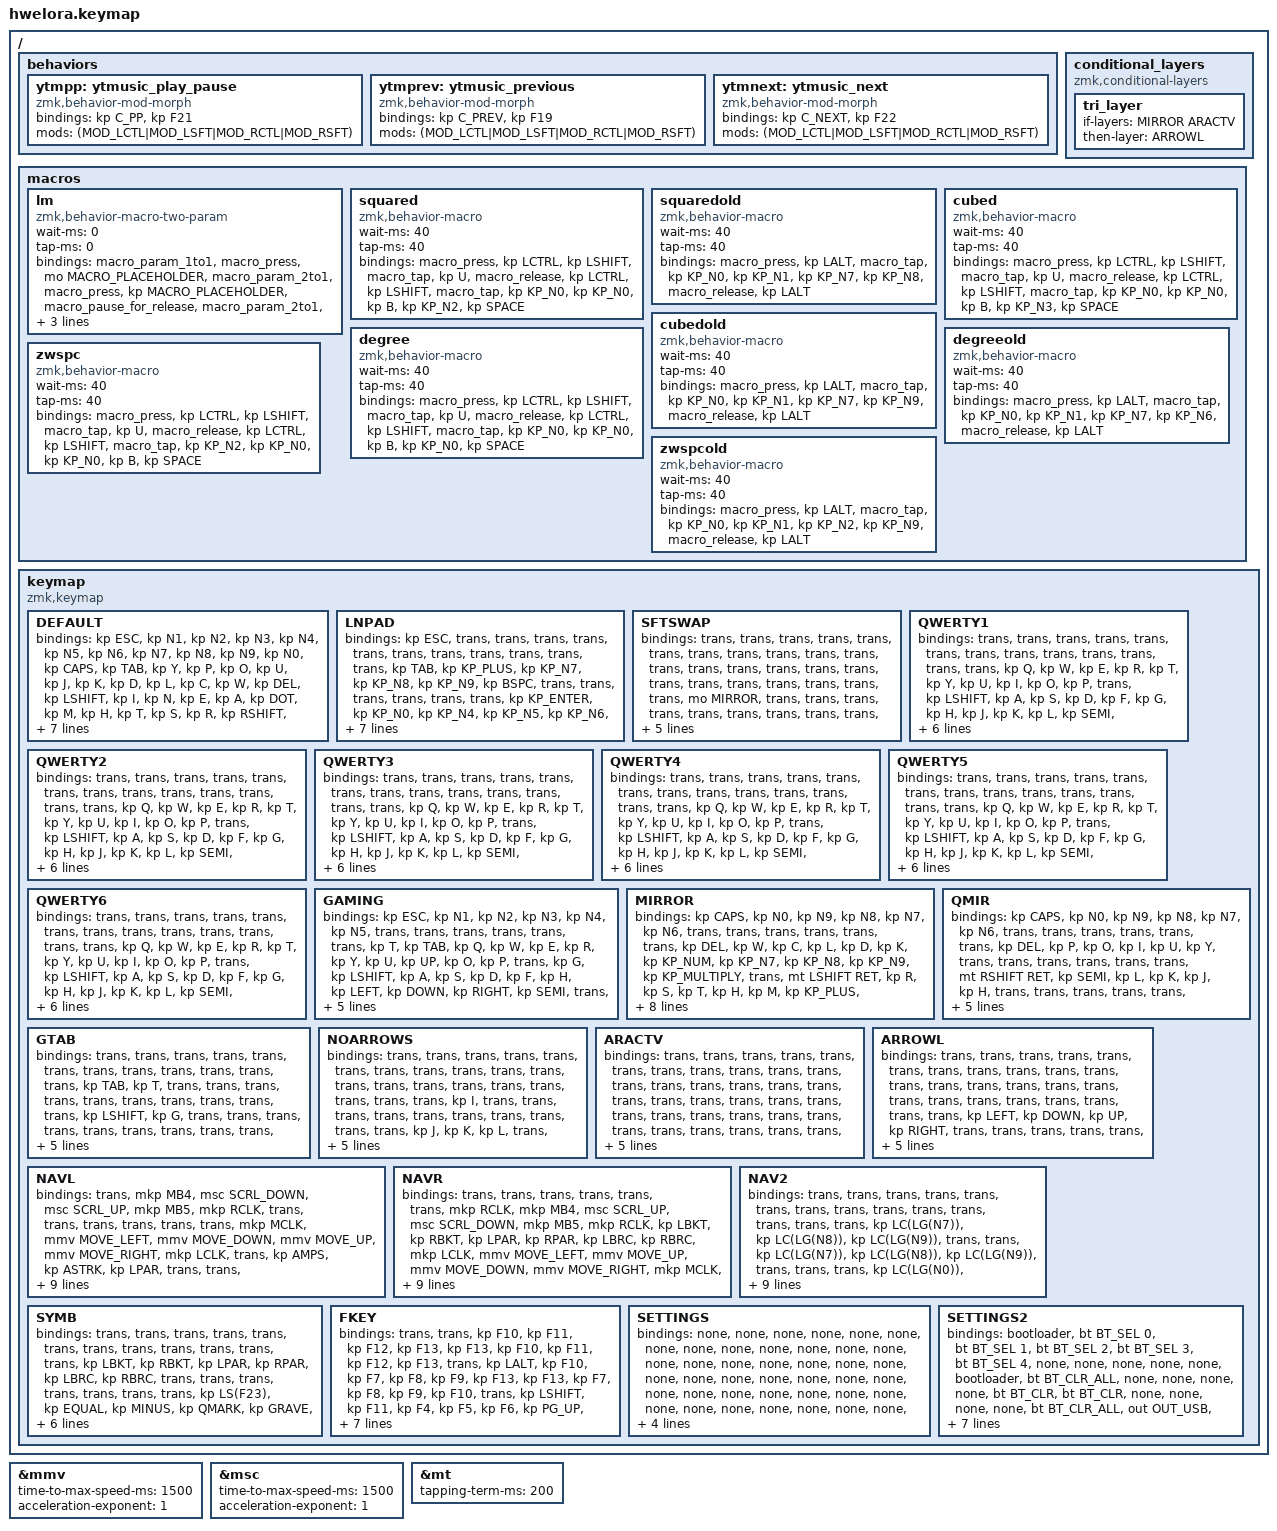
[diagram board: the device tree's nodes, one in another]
#include <behaviors.dtsi>
#include <dt-bindings/zmk/keys.h>
#include <dt-bindings/zmk/bt.h>
#include <dt-bindings/zmk/outputs.h>
#define ZMK_POINTING_DEFAULT_MOVE_VAL 2000
#define ZMK_POINTING_DEFAULT_SCRL_VAL 200 
#include <dt-bindings/zmk/pointing.h>
&mmv {
    time-to-max-speed-ms = <1500>;
    acceleration-exponent = <1>;
};
&msc {
    time-to-max-speed-ms = <1500>;
    acceleration-exponent = <1>;
};

#define DEFAULT 0
#define LNPAD	1
#define SFTSWAP 2
#define QWERTY1   3
#define QWERTY2   4
#define QWERTY3   5
#define QWERTY4   6
#define QWERTY5   7
#define QWERTY6   8
#define GAMING   9
#define MIRROR   10
#define QMIR   11
#define GTAB   12
#define NOARROWS   13
#define ARACTV   14
#define ARROWL   15
#define NAVL   16
#define NAVR   17
#define NAV2   18
#define SYMB   19
#define FKEY   20
#define SETTINGS   21
#define SETTINGS2   22

/ {
    behaviors {
        ytmpp: ytmusic_play_pause {
            compatible = "zmk,behavior-mod-morph";
            #binding-cells = <0>;
            bindings = <&kp C_PP>, <&kp F21>;
            mods = <(MOD_LCTL|MOD_LSFT|MOD_RCTL|MOD_RSFT)>;
        };
		ytmprev: ytmusic_previous {
            compatible = "zmk,behavior-mod-morph";
            #binding-cells = <0>;
            bindings = <&kp C_PREV>, <&kp F19>;
            mods = <(MOD_LCTL|MOD_LSFT|MOD_RCTL|MOD_RSFT)>;
        };
		ytmnext: ytmusic_next {
            compatible = "zmk,behavior-mod-morph";
            #binding-cells = <0>;
            bindings = <&kp C_NEXT>, <&kp F22>;
            mods = <(MOD_LCTL|MOD_LSFT|MOD_RCTL|MOD_RSFT)>;
        };
    };
};

/ {
    conditional_layers {
        compatible = "zmk,conditional-layers";
        tri_layer {
            if-layers = <MIRROR ARACTV>;
            then-layer = <ARROWL>;
        };
    };
};

/ {
    macros {
        lm: lm {
			compatible = "zmk,behavior-macro-two-param";
			wait-ms = <0>;
			tap-ms = <0>;
			#binding-cells = <2>;
			bindings
				= <&macro_param_1to1>
				, <&macro_press &mo MACRO_PLACEHOLDER>
				, <&macro_param_2to1>
				, <&macro_press &kp MACRO_PLACEHOLDER>
				, <&macro_pause_for_release>
				, <&macro_param_2to1>
				, <&macro_release &kp MACRO_PLACEHOLDER>
				, <&macro_param_1to1>
				// if all modifiers are released
					, <&macro_release &mo MACRO_PLACEHOLDER>
				// else
				// return
				;
		};
		squared: squared {
			compatible = "zmk,behavior-macro";
			wait-ms = <40>;
			tap-ms = <40>;
			#binding-cells = <0>;
			bindings
				= <&macro_press   &kp LCTRL &kp LSHIFT>
				, <&macro_tap     &kp U>
				, <&macro_release &kp LCTRL &kp LSHIFT>
				, <&macro_tap     &kp KP_N0 &kp KP_N0 &kp B &kp KP_N2 &kp SPACE>
			;
		};
		squaredold: squaredold {
			compatible = "zmk,behavior-macro";
			wait-ms = <40>;
			tap-ms = <40>;
			#binding-cells = <0>;
			bindings
				= <&macro_press   &kp LALT>
				, <&macro_tap     &kp KP_N0 &kp KP_N1 &kp KP_N7 &kp KP_N8>
				, <&macro_release &kp LALT>
			;
		};
		cubed: cubed {
			compatible = "zmk,behavior-macro";
			wait-ms = <40>;
			tap-ms = <40>;
			#binding-cells = <0>;
			bindings
				= <&macro_press   &kp LCTRL &kp LSHIFT>
				, <&macro_tap     &kp U>
				, <&macro_release &kp LCTRL &kp LSHIFT>
				, <&macro_tap     &kp KP_N0 &kp KP_N0 &kp B &kp KP_N3 &kp SPACE>
				;
		};
		cubedold: cubedold {
			compatible = "zmk,behavior-macro";
			wait-ms = <40>;
			tap-ms = <40>;
			#binding-cells = <0>;
			bindings
				= <&macro_press   &kp LALT>
				, <&macro_tap     &kp KP_N0 &kp KP_N1 &kp KP_N7 &kp KP_N9>
				, <&macro_release &kp LALT>
				;
		};
        degree: degree {
			compatible = "zmk,behavior-macro";
			wait-ms = <40>;
			tap-ms = <40>;
			#binding-cells = <0>;
			bindings
				= <&macro_press   &kp LCTRL &kp LSHIFT>
				, <&macro_tap     &kp U>
				, <&macro_release &kp LCTRL &kp LSHIFT>
				, <&macro_tap     &kp KP_N0 &kp KP_N0 &kp B &kp KP_N0 &kp SPACE>
				;
		};
		degreeold: degreeold {
			compatible = "zmk,behavior-macro";
			wait-ms = <40>;
			tap-ms = <40>;
			#binding-cells = <0>;
			bindings
				= <&macro_press   &kp LALT>
				, <&macro_tap     &kp KP_N0 &kp KP_N1 &kp KP_N7 &kp KP_N6>
				, <&macro_release &kp LALT>
				;
		};
        zwspc: zwspc {
            compatible = "zmk,behavior-macro";
			wait-ms = <40>;
			tap-ms = <40>;
			#binding-cells = <0>;
			bindings
				= <&macro_press   &kp LCTRL &kp LSHIFT>
				, <&macro_tap     &kp U>
				, <&macro_release &kp LCTRL &kp LSHIFT>
                , <&macro_tap     &kp KP_N2 &kp KP_N0 &kp KP_N0 &kp B &kp SPACE>
				;
		};
		zwspcold: zwspcold {
			compatible = "zmk,behavior-macro";
			wait-ms = <40>;
			tap-ms = <40>;
			#binding-cells = <0>;
			bindings
				= <&macro_press   &kp LALT>
				, <&macro_tap     &kp KP_N0 &kp KP_N1 &kp KP_N2 &kp KP_N9>
				, <&macro_release &kp LALT>
				;
		};
    };
};

&mt {
    tapping-term-ms = <200>;
};

/ {
    keymap {
        compatible = "zmk,keymap";

        DEFAULT {
            bindings = <
	&kp ESC    		 &kp N1   &kp N2   &kp N3    	   &kp N4    		&kp N5                                                    &kp N6     &kp N7    		 &kp N8   &kp N9    &kp N0   &kp CAPS
    &kp TAB    		 &kp Y    &kp P    &kp O     	   &kp U     		&kp J                                                     &kp K      &kp D     	 	 &kp L    &kp C     &kp W    &kp DEL
    &kp LSHIFT 		 &kp I    &kp N    &kp E     	   &kp A     		&kp DOT                                                   &kp M      &kp H    		 &kp T    &kp S     &kp R    &kp RSHIFT
    &lm QWERTY1 LCTRL &kp Q    &kp Z    &kp APOS  	   &kp COMMA 		&kp SEMI   &to DEFAULT &mo SYMB    &kp F13    &kp DEL 	  &kp B      &kp F    		 &kp G    &kp V     &kp X    &lm QWERTY6 RCTRL
									   &lm QWERTY2 LGUI &lm QWERTY3 LALT  &mo NAVL   &kp SPACE   &mo MIRROR  &mo NAVR   &kp BSPC    &kp RET    &lm QWERTY4 RALT &lm QWERTY5 LGUI
            >;
        };
		
		LNPAD {
            bindings = <
	&kp ESC 	 &trans 	  &trans 	&trans 	  &trans		&trans                         	  			  	  &trans &trans &trans &trans &trans &trans
    &kp TAB 	 &kp KP_PLUS  &kp KP_N7 &kp KP_N8 &kp KP_N9 &kp BSPC                        	      			  &trans &trans &trans &trans &trans &trans
    &kp KP_ENTER &kp KP_N0 	  &kp KP_N4 &kp KP_N5 &kp KP_N6 &kp KP_MULTIPLY                                	      &trans &trans &trans &trans &trans &trans
    &trans		 &kp KP_MINUS &kp KP_N1 &kp KP_N2 &kp KP_N3 &kp KP_DIVIDE &to DEFAULT   &trans 		&trans &trans &trans &trans &trans &trans &trans &trans
										&trans 	  &trans 	&kp KP_DOT 	  &trans 		&trans  	&trans &trans &trans &trans &trans
            >;
        };
		SFTSWAP {
            bindings = <
	&trans     &trans    &trans    &trans    &trans   &trans                                        &trans     &trans    &trans   &trans    &trans   &trans
    &trans     &trans    &trans    &trans    &trans   &trans                                        &trans     &trans    &trans   &trans    &trans   &trans
    &mo MIRROR &trans    &trans    &trans    &trans   &trans                                   	    &trans     &trans    &trans   &trans    &trans   &kp RET
    &trans     &trans    &trans    &trans    &trans   &trans 	 &trans    &trans    &trans &trans  &trans     &trans    &trans   &trans    &trans   &trans
								   &trans    &trans   &kp LSHIFT &trans    &trans    &trans &trans  &kp RSHIFT &trans    &trans
            >;
        };
		QWERTY1 {
            bindings = <
	&trans     &trans   &trans   &trans    &trans    &trans                                          &trans    &trans    &trans    &trans    &trans   &trans
    &trans     &kp Q    &kp W    &kp E     &kp R     &kp T                                           &kp Y     &kp U     &kp I     &kp O     &kp P    &trans
    &kp LSHIFT &kp A    &kp S    &kp D     &kp F     &kp G                                           &kp H     &kp J     &kp K     &kp L     &kp SEMI &mt RSHIFT RET
    &kp LCTRL  &kp Z    &kp X    &kp C     &kp V 	 &kp B      &trans   &trans    &trans   &trans   &kp N     &kp M     &kp COMMA &kp DOT   &kp FSLH &kp RCTRL
                                 &kp LGUI  &trans    &kp LSHIFT &trans   &mo QMIR  &trans   &trans   &trans    &kp RALT  &kp RGUI
            >;
        };
		QWERTY2 {
            bindings = <
	&trans     &trans   &trans   &trans    &trans    &trans                                          &trans    &trans    &trans    &trans    &trans   &trans
    &trans     &kp Q    &kp W    &kp E     &kp R     &kp T                                           &kp Y     &kp U     &kp I     &kp O     &kp P    &trans
    &kp LSHIFT &kp A    &kp S    &kp D     &kp F     &kp G                                           &kp H     &kp J     &kp K     &kp L     &kp SEMI &mt RSHIFT RET
    &kp LCTRL  &kp Z    &kp X    &kp C     &kp V 	 &kp B      &trans   &trans    &trans   &trans   &kp N     &kp M     &kp COMMA &kp DOT   &kp FSLH &kp RCTRL
                                 &kp LGUI  &trans    &kp LSHIFT &trans   &mo QMIR  &trans   &trans   &trans    &kp RALT  &kp RGUI
            >;
        };
		QWERTY3 {
            bindings = <
	&trans     &trans   &trans   &trans    &trans    &trans                                          &trans    &trans    &trans    &trans    &trans   &trans
    &trans     &kp Q    &kp W    &kp E     &kp R     &kp T                                           &kp Y     &kp U     &kp I     &kp O     &kp P    &trans
    &kp LSHIFT &kp A    &kp S    &kp D     &kp F     &kp G                                           &kp H     &kp J     &kp K     &kp L     &kp SEMI &mt RSHIFT RET
    &kp LCTRL  &kp Z    &kp X    &kp C     &kp V 	 &kp B      &trans   &trans    &trans   &trans   &kp N     &kp M     &kp COMMA &kp DOT   &kp FSLH &kp RCTRL
                                 &kp LGUI  &trans    &kp LSHIFT &trans   &mo QMIR  &trans   &trans   &trans    &kp RALT  &kp RGUI
            >;
        };
		QWERTY4 {
            bindings = <
	&trans     &trans   &trans   &trans    &trans    &trans                                          &trans    &trans    &trans    &trans    &trans   &trans
    &trans     &kp Q    &kp W    &kp E     &kp R     &kp T                                           &kp Y     &kp U     &kp I     &kp O     &kp P    &trans
    &kp LSHIFT &kp A    &kp S    &kp D     &kp F     &kp G                                           &kp H     &kp J     &kp K     &kp L     &kp SEMI &mt RSHIFT RET
    &kp LCTRL  &kp Z    &kp X    &kp C     &kp V 	 &kp B      &trans   &trans    &trans   &trans   &kp N     &kp M     &kp COMMA &kp DOT   &kp FSLH &kp RCTRL
                                 &kp LGUI  &trans    &kp LSHIFT &trans   &mo QMIR  &trans   &trans   &trans    &kp RALT  &kp RGUI
            >;
        };
		QWERTY5 {
            bindings = <
	&trans     &trans   &trans   &trans    &trans    &trans                                          &trans    &trans    &trans    &trans    &trans   &trans
    &trans     &kp Q    &kp W    &kp E     &kp R     &kp T                                           &kp Y     &kp U     &kp I     &kp O     &kp P    &trans
    &kp LSHIFT &kp A    &kp S    &kp D     &kp F     &kp G                                           &kp H     &kp J     &kp K     &kp L     &kp SEMI &mt RSHIFT RET
    &kp LCTRL  &kp Z    &kp X    &kp C     &kp V 	 &kp B      &trans   &trans    &trans   &trans   &kp N     &kp M     &kp COMMA &kp DOT   &kp FSLH &kp RCTRL
                                 &kp LGUI  &trans    &kp LSHIFT &trans   &mo QMIR  &trans   &trans   &trans    &kp RALT  &kp RGUI
            >;
        };
        QWERTY6 {
            bindings = <
	&trans     &trans   &trans   &trans    &trans    &trans                                          &trans    &trans    &trans    &trans    &trans   &trans
    &trans     &kp Q    &kp W    &kp E     &kp R     &kp T                                           &kp Y     &kp U     &kp I     &kp O     &kp P    &trans
    &kp LSHIFT &kp A    &kp S    &kp D     &kp F     &kp G                                           &kp H     &kp J     &kp K     &kp L     &kp SEMI &mt RSHIFT RET
    &kp LCTRL  &kp Z    &kp X    &kp C     &kp V 	 &kp B      &trans   &trans    &trans   &trans   &kp N     &kp M     &kp COMMA &kp DOT   &kp FSLH &kp RCTRL
                                 &kp LGUI  &trans    &kp LSHIFT &trans   &mo QMIR  &trans   &trans   &trans    &kp RALT  &kp RGUI
            >;
        };
		GAMING {
            bindings = <
	&kp ESC &kp N1     &kp N2   &kp N3    &kp N4    	 &kp N5                                        &trans    &trans    &trans    &trans    &trans   &trans
    &kp T   &kp TAB    &kp Q    &kp W     &kp E     	 &kp R                                         &kp Y     &kp U     &kp UP    &kp O     &kp P    &trans
    &kp G   &kp LSHIFT &kp A	&kp S     &kp D    	 	 &kp F                                         &kp H     &kp LEFT  &kp DOWN  &kp RIGHT &kp SEMI &trans
    &kp B   &kp LCTRL  &kp Z    &kp X     &kp C     	 &kp V    &trans   &trans    &trans   &trans   &kp N     &kp M     &kp COMMA &kp DOT   &kp FSLH &kp RCTRL
                                &kp K_APP &lm GTAB LALT  &mo NAVL &trans   &mo QMIR  &trans   &trans   &trans    &kp RALT  &none
            >;
        };
		MIRROR {
            bindings = <
	&kp CAPS 	   &kp N0   &kp N9   &kp N8    		 &kp N7    	   &kp N6                                                   &trans    	  &trans    &trans    &trans    &trans           &trans
    &kp DEL    	   &kp W    &kp C    &kp L     		 &kp D     	   &kp K                                                    &kp KP_NUM 	  &kp KP_N7 &kp KP_N8 &kp KP_N9 &kp KP_MULTIPLY  &trans
    &mt LSHIFT RET &kp R    &kp S    &kp T     		 &kp H     	   &kp M                                                    &kp KP_PLUS   &kp KP_N4 &kp KP_N5 &kp KP_N6 &kp KP_N0        &kp KP_ENTER
    &lm QMIR RCTRL &kp X    &kp V    &kp G     		 &kp F   	   &kp B    &tog LNPAD   &mo FKEY   &tog NOARROWS &kp F14   &kp KP_MINUS  &kp KP_N1 &kp KP_N2 &kp KP_N3 &kp KP_DIVIDE    &trans
									 &lm QMIR RGUI   &lm QMIR RALT &kp BSPC &trans       &trans     &tog ARACTV   &trans    &kp KP_DOT    &trans    &trans
            >;
        };
		QMIR {
            bindings = <
	&kp CAPS   	   &kp N0   &kp N9   &kp N8    &kp N7   &kp N6                                            &trans    &trans    &trans    &trans    &trans   &trans
    &kp DEL		   &kp P    &kp O    &kp I     &kp U    &kp Y                                             &trans    &trans    &trans    &trans    &trans   &trans
    &mt RSHIFT RET &kp SEMI &kp L    &kp K     &kp J    &kp H                                             &trans    &trans    &trans    &trans    &trans   &trans
    &kp RCTRL	   &kp FSLH &kp DOT  &kp COMMA &kp M    &kp N    &trans  &mo FKEY  &tog NOARROWS &kp F14  &trans    &trans    &trans    &trans    &trans   &trans
								     &kp RGUI  &kp RALT &kp BSPC &trans  &trans    &trans        &trans   &trans    &trans    &trans
            >;
        };
		GTAB {
            bindings = <
	&trans     &trans    &trans    &trans    &trans   &trans                                      &trans   &trans    &trans   &trans    &trans   &trans
    &kp TAB    &kp T     &trans    &trans    &trans   &trans                                      &trans   &trans    &trans   &trans    &trans   &trans
    &kp LSHIFT &kp G     &trans    &trans    &trans   &trans                                   	  &trans   &trans    &trans   &trans    &trans   &trans
    &kp LCTRL  &kp B     &trans    &trans    &trans   &trans   &trans    &trans    &trans &trans  &trans   &trans    &trans   &trans    &trans   &trans
								   &trans    &trans   &trans   &trans    &trans    &trans &trans  &trans   &trans    &trans
            >;
        };
		NOARROWS {
            bindings = <
	&trans    &trans    &trans    &trans    &trans   &trans                                    &trans    &trans    &trans   &trans    &trans   &trans
    &trans    &trans    &trans    &trans    &trans   &trans                                    &trans    &trans    &kp I    &trans    &trans   &trans
    &trans    &trans    &trans    &trans    &trans   &trans                                    &trans    &kp J     &kp K    &kp L 	  &trans   &kp RET
    &trans    &trans    &trans    &trans    &trans   &trans &trans    &trans    &trans &trans  &trans    &trans    &trans   &trans    &trans   &trans
								  &trans    &trans   &trans &trans    &trans    &kp N1 &kp N2  &kp N3    &trans    &trans
            >;
        };
		ARACTV {
            bindings = <
	&trans    &trans    &trans    &trans    &trans    &trans                                    &trans    &trans    &trans    &trans    &trans   &trans
    &trans    &trans    &trans    &trans    &trans    &trans  					                &trans    &trans    &trans    &trans    &trans   &trans
    &trans    &trans    &trans    &trans    &trans    &trans                                    &trans    &trans  	&trans    &trans 	&trans   &trans
    &trans    &trans    &trans    &trans    &trans    &trans &trans    &trans    &trans &trans  &trans    &trans    &trans    &trans    &trans   &trans
								  &trans    &trans    &trans &trans    &trans    &trans &trans  &trans    &trans    &trans
            >;
        };
		ARROWL {
            bindings = <
	&trans    &trans    &trans    &trans    &trans    &trans                                    &trans    &trans    &trans    &trans    &trans   &trans
    &trans    &trans    &trans    &trans    &trans    &trans  					                &trans    &trans    &trans    &trans    &trans   &trans
    &trans    &kp LEFT  &kp DOWN  &kp UP    &kp RIGHT &trans                                    &trans    &trans  	&trans    &trans 	&trans   &trans
    &trans    &trans    &trans    &trans    &trans    &trans &trans    &trans    &trans &trans  &trans    &trans    &trans    &trans    &trans   &trans
								  &trans    &trans    &trans &trans    &trans    &trans &trans  &trans    &trans    &trans
            >;
        };
		NAVL {
            bindings = <
	&trans  	     &mkp MB4 	    &msc SCRL_DOWN &msc SCRL_UP &mkp MB5 	    &mkp RCLK                                          	  &trans    &trans    &trans    &trans    &trans   &trans
    &mkp MCLK  	     &mmv MOVE_LEFT &mmv MOVE_DOWN &mmv MOVE_UP &mmv MOVE_RIGHT &mkp LCLK                       	    			  &trans    &kp AMPS  &kp ASTRK &kp LPAR  &trans   &trans
    &mt LSHIFT RET   &kp LEFT  	    &kp DOWN   	   &kp UP    	&kp RIGHT  	    &kp C_VOL_UP                                    	  &kp GRAVE &kp DLLR  &kp PRCNT &kp CARET &kp RPAR &trans
    &lm QWERTY1 LCTRL &mo NAV2  	    &ytmprev 	   &ytmpp	    &ytmnext 	    &kp C_VOL_DN &tog SFTSWAP &trans    &trans   &trans   &trans    &kp EXCL  &kp AT    &kp HASH  &trans   &trans
												   &trans       &trans     	    &trans	     &trans       &kp K_APP &mo FKEY &trans   &trans    &trans    &trans
            >;
        };
	
		NAVR {
            bindings = <
	&trans     &trans      &trans      &trans    &trans    &trans                                          	  &mkp RCLK      &mkp MB4 	    &msc SCRL_UP &msc SCRL_DOWN &mkp MB5 	    &mkp RCLK
    &kp LBKT   &kp RBKT    &kp LPAR    &kp RPAR  &kp LBRC  &kp RBRC                                        	  &mkp LCLK      &mmv MOVE_LEFT &mmv MOVE_UP &mmv MOVE_DOWN &mmv MOVE_RIGHT &mkp MCLK
    &kp LSHIFT &kp LS(F23) &kp EQUAL   &kp MINUS &kp QMARK &kp GRAVE                                       	  &kp C_VOL_UP   &kp LEFT   	&kp UP       &kp DOWN	    &kp RIGHT 	    &mt RSHIFT RET
    &kp LCTRL  &kp LC(F23) &kp LA(F23) &kp UNDER &kp FSLH  &kp BSLH &kp F23 &trans      &mo FKEY &tog NOARROWS &kp C_VOL_DN   &ytmprev 	    &ytmpp 	     &ytmnext 	    &mo NAV2  	    &trans
                                       &trans    &trans    &trans   &trans  &mo FKEY	&trans   &trans 	      &trans	     &trans     	&trans
            >;
        };
		NAV2 {
            bindings = <
	&trans    &trans    		&trans    		  &trans    		&trans 			 &trans                                     	 &trans    &trans    		 &trans    		   &trans    	 	&trans   		 &trans
    &trans    &trans    		&kp LC(LG(N7))    &kp LC(LG(N8))    &kp LC(LG(N9))   &trans                                     	 &trans    &kp LC(LG(N7))    &kp LC(LG(N8))    &kp LC(LG(N9))   &trans  		 &trans    
    &trans    &kp LC(LG(N0))    &kp LC(LG(N4))    &kp LC(LG(N5))    &kp LC(LG(N6))   &trans                                     	 &trans    &kp LC(LG(N4))    &kp LC(LG(N5))    &kp LC(LG(N6))   &kp LC(LG(N0))   &trans    
    &trans    &trans    		&kp LC(LG(N1))    &kp LC(LG(N2))    &kp LC(LG(N3))   &trans &tog QWERTY1 &trans    &trans &tog QWERTY1 &trans    &kp LC(LG(N1))    &kp LC(LG(N2))    &kp LC(LG(N3))   &trans  		 &trans
												  &trans    		&trans   		 &trans &trans      &trans    &trans &trans  	 &trans    &trans    		 &trans
            >;
        };
		SYMB {
            bindings = <
	&trans    &trans      &trans      &trans    &trans    &trans                                          	&trans &trans &trans &trans &trans &trans
    &kp LBKT  &kp RBKT    &kp LPAR    &kp RPAR  &kp LBRC  &kp RBRC                                        	&trans &trans &trans &trans &trans &trans
    &trans    &kp LS(F23) &kp EQUAL   &kp MINUS &kp QMARK &kp GRAVE                                       	&trans &trans &trans &trans &trans &trans
    &trans    &kp LC(F23) &kp LA(F23) &kp UNDER &kp FSLH  &kp BSLH &to GAMING &trans   &trans &trans &trans &trans &trans &trans &trans &trans
									  &trans    &trans    &trans   &trans     &none	   &trans &trans &trans	&trans &trans
            >;
        };
		FKEY {
            bindings = <
	&trans     &trans    &kp F10   &kp F11   &kp F12  &kp F13                                   	       &kp F13   &kp F10   &kp F11   &kp F12   &kp F13  &trans
    &kp LALT   &kp F10   &kp F7    &kp F8    &kp F9   &kp F13                                    	       &kp F13   &kp F7    &kp F8    &kp F9    &kp F10  &trans
    &kp LSHIFT &kp F11   &kp F4    &kp F5    &kp F6   &kp PG_UP                                    	       &kp HOME  &kp F4    &kp F5    &kp F6    &kp F11  &trans
    &trans     &kp F12   &kp F1    &kp F2    &kp F3   &kp PG_DN &to GAMING   &trans    &trans &to DEFAULT  &kp END   &kp F1    &kp F2    &kp F3    &kp F12  &trans
								   &trans    &trans   &trans    &mo SETTINGS &none     &trans &mo SETTINGS &trans    &trans    &trans
            >;
        };
		SETTINGS {
            bindings = <
	&none &none &none &none &none &none                         	  				&none &none &none &none &none &none
    &none &none &none &none &none &none                        	      				&none &none &none &none &none &none
    &none &none &none &none &none &none                                	    		&none &none &none &none &none &none
    &none &none &none &none &none &none &mo SETTINGS2  &none    &none &mo SETTINGS2 &none &none &none &none &none &none
					  &none &none &none &none          &none    &none &none  	    &none &none &none
            >;
        };
		SETTINGS2 {
            bindings = <
	&bootloader    &bt BT_SEL 0 &bt BT_SEL 1 &bt BT_SEL 2 &bt BT_SEL 3 &bt BT_SEL 4                         	  		&none  	   		&none  &none    &none   &none   &bootloader
    &bt BT_CLR_ALL &none    	&none    	 &none    	  &none   	   &bt BT_CLR                        	      		&bt BT_CLR 		&none  &none    &none   &none   &bt BT_CLR_ALL
    &out OUT_USB   &none    	&none    	 &none    	  &none   	   &studio_unlock                          	  		&studio_unlock  &none  &none    &none   &none   &out OUT_USB
    &out OUT_BLE   &none    	&none    	 &none    	  &none   	   &none 		&to DEFAULT    &none    &to DEFAULT &none  	   		&none  &none    &none   &none   &out OUT_BLE
										     &none    	  &none   	   &none 		&none          &none    &none 		&none  	   		&none  &none    &none
            >;
        };
    };
};
